CM_ "IMPORT _honda_common.dbc";
CM_ "IMPORT _nidec_common.dbc";
CM_ "IMPORT _steering_control_a.dbc";
CM_ "IMPORT _steering_sensors_b.dbc";

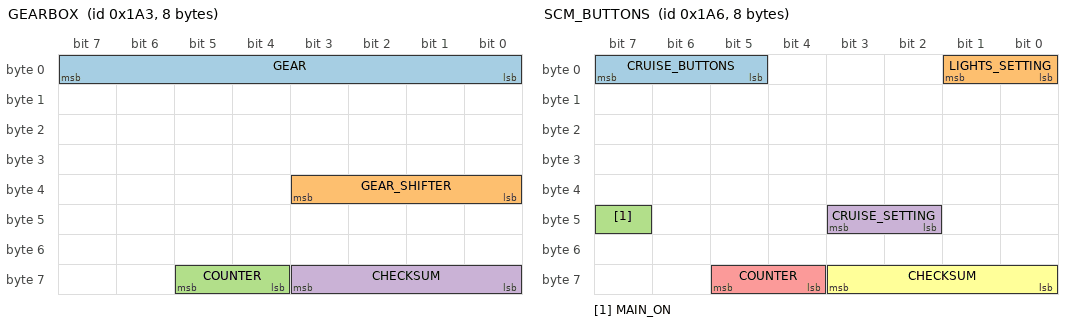
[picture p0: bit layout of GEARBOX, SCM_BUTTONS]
BO_ 419 GEARBOX: 8 PCM
 SG_ GEAR : 7|8@0+ (1,0) [0|256] "" EON
 SG_ GEAR_SHIFTER : 35|4@0+ (1,0) [0|15] "" EON
 SG_ COUNTER : 61|2@0+ (1,0) [0|3] "" EON
 SG_ CHECKSUM : 59|4@0+ (1,0) [0|3] "" EON

BO_ 422 SCM_BUTTONS: 8 SCM
 SG_ CRUISE_BUTTONS : 7|3@0+ (1,0) [0|7] "" EON
 SG_ LIGHTS_SETTING : 1|2@0+ (1,0) [0|3] "" EON
 SG_ MAIN_ON : 47|1@0+ (1,0) [0|1] "" EON
 SG_ CRUISE_SETTING : 43|2@0+ (1,0) [0|3] "" EON
 SG_ COUNTER : 61|2@0+ (1,0) [0|3] "" EON
 SG_ CHECKSUM : 59|4@0+ (1,0) [0|3] "" EON

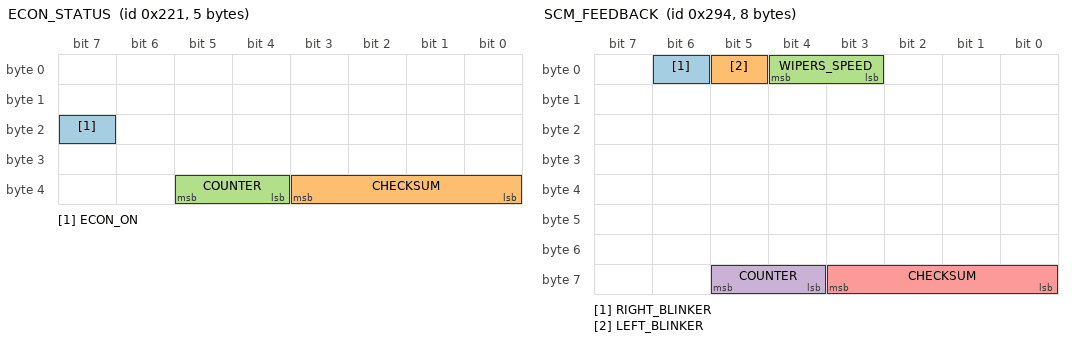
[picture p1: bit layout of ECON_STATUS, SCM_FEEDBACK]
BO_ 545 ECON_STATUS: 5 XXX
 SG_ ECON_ON : 23|1@0+ (1,0) [0|1] "" EON
 SG_ CHECKSUM : 35|4@0+ (1,0) [0|3] "" EON
 SG_ COUNTER : 37|2@0+ (1,0) [0|3] "" EON

BO_ 660 SCM_FEEDBACK: 8 SCM
 SG_ RIGHT_BLINKER : 6|1@0+ (1,0) [0|1] "" EON
 SG_ LEFT_BLINKER : 5|1@0+ (1,0) [0|1] "" EON
 SG_ WIPERS_SPEED : 4|2@0+ (1,0) [0|3] "" EON
 SG_ COUNTER : 61|2@0+ (1,0) [0|3] "" EON
 SG_ CHECKSUM : 59|4@0+ (1,0) [0|15] "" EON

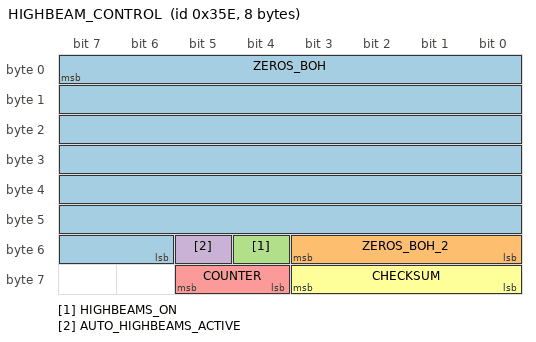
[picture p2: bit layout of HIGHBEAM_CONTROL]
BO_ 862 HIGHBEAM_CONTROL: 8 ADAS
 SG_ ZEROS_BOH : 7|50@0+ (1,0) [0|127] "" BDY
 SG_ ZEROS_BOH_2 : 48|4@1+ (1,0) [0|15] "" XXX
 SG_ HIGHBEAMS_ON : 52|1@0+ (1,0) [0|1] "" XXX
 SG_ AUTO_HIGHBEAMS_ACTIVE : 53|1@0+ (1,0) [0|1] "" XXX
 SG_ COUNTER : 61|2@0+ (1,0) [0|3] "" XXX
 SG_ CHECKSUM : 59|4@0+ (1,0) [0|15] "" XXX

CM_ SG_ 419 GEAR "10 = reverse, 11 = transition";

VAL_ 419 GEAR_SHIFTER 10 "S" 4 "D" 3 "N" 2 "R" 1 "P" ;
VAL_ 422 CRUISE_BUTTONS 7 "tbd" 6 "tbd" 5 "tbd" 4 "accel_res" 3 "decel_set" 2 "cancel" 1 "main" 0 "none" ;
VAL_ 422 LIGHTS_SETTING 3 "high_beam" 2 "low_beam" 1 "position" 0 "no_lights" ;
VAL_ 422 CRUISE_SETTING 3 "distance_adj" 2 "tbd" 1 "lkas_button" 0 "none" ;
